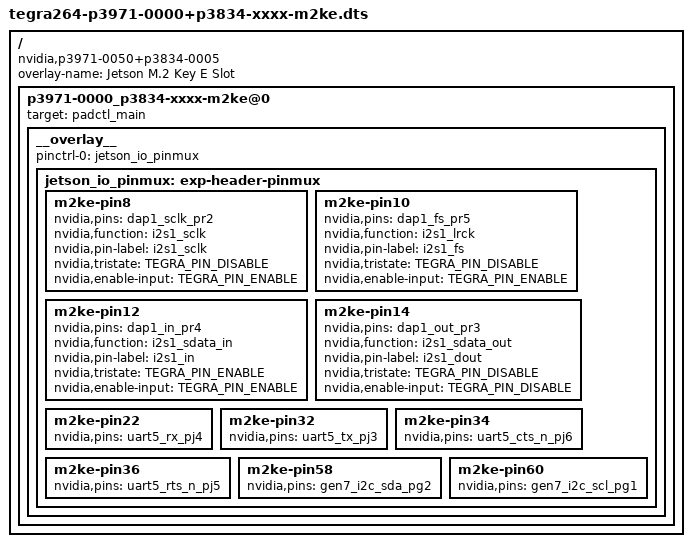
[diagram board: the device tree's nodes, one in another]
// SPDX-License-Identifier: GPL-2.0-only
// SPDX-FileCopyrightText: Copyright (c) 2025, NVIDIA CORPORATION & AFFILIATES.  All rights reserved.
/*
 * Device-tree overlay for M.2 Key E Expansion Header.
 */

/dts-v1/;
/plugin/;

#include <dt-bindings/pinctrl/pinctrl-tegra.h>
#include <dt-bindings/gpio/tegra264-gpio.h>

/ {
	overlay-name = "Jetson M.2 Key E Slot";
	compatible = "nvidia,p3971-0050+p3834-0005", "nvidia,p3971-0080+p3834-0008", "nvidia,p3971-0089+p3834-0008";

	p3971-0000_p3834-xxxx-m2ke@0 {
		target = <&padctl_main>;
		__overlay__ {
			pinctrl-names = "default";
			pinctrl-0 = <&jetson_io_pinmux>;
			jetson_io_pinmux: exp-header-pinmux {
				m2ke-pin8 {
					nvidia,pins = "dap1_sclk_pr2";
					nvidia,function = "i2s1_sclk";
					nvidia,pin-label = "i2s1_sclk";
					nvidia,tristate = <TEGRA_PIN_DISABLE>;
					nvidia,enable-input = <TEGRA_PIN_ENABLE>;
				};
				m2ke-pin10 {
					nvidia,pins = "dap1_fs_pr5";
					nvidia,function = "i2s1_lrck";
					nvidia,pin-label = "i2s1_fs";
					nvidia,tristate = <TEGRA_PIN_DISABLE>;
					nvidia,enable-input = <TEGRA_PIN_ENABLE>;
				};
				m2ke-pin12 {
					nvidia,pins = "dap1_in_pr4";
					nvidia,function = "i2s1_sdata_in";
					nvidia,pin-label = "i2s1_in";
					nvidia,tristate = <TEGRA_PIN_ENABLE>;
					nvidia,enable-input = <TEGRA_PIN_ENABLE>;
				};
				m2ke-pin14 {
					nvidia,pins = "dap1_out_pr3";
					nvidia,function = "i2s1_sdata_out";
					nvidia,pin-label = "i2s1_dout";
					nvidia,tristate = <TEGRA_PIN_DISABLE>;
					nvidia,enable-input = <TEGRA_PIN_DISABLE>;
				};
				m2ke-pin22 {
					nvidia,pins = "uart5_rx_pj4";
				};
				m2ke-pin32 {
					nvidia,pins = "uart5_tx_pj3";
				};
				m2ke-pin34 {
					nvidia,pins = "uart5_cts_n_pj6";
				};
				m2ke-pin36 {
					nvidia,pins = "uart5_rts_n_pj5";
				};
				m2ke-pin58 {
					nvidia,pins = "gen7_i2c_sda_pg2";
				};
				m2ke-pin60 {
					nvidia,pins = "gen7_i2c_scl_pg1";
				};
			};
		};
	};
};
